# STM32WBA54 register map
File version: 1.0
CPU: CM33 r0p1, little endian, MPU, FPU, 4 interrupt priority bits
Registers are 32-bit, read-write, reset 0x0 unless marked. A register's access mark holds for its fields unless they carry their own. Offsets are from the block's base; [hi:lo] are bit positions; lines under a group give offsets from that group; {n}, {i} and the like mark numbered series; 'fields as' and 'values as' point back to an identical list.

## TSC — Touch sensing controller
Base 0x40024000
Same registers: SEC_TSC 0x50024000
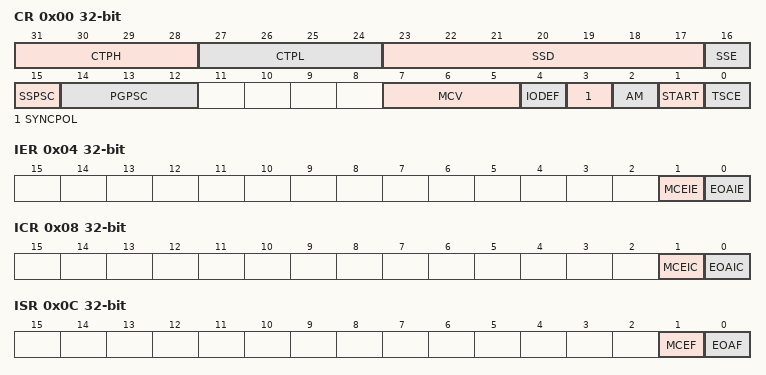
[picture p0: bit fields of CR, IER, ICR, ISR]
0x00 CR — TSC control register
  [31:28] CTPH — Charge transfer pulse high These bits are set and cleared by software. They define the duration of the high state of the charge transfer pulse (charge of CsubX/sub). ... Note: These bits must not be modified when an acquisition is ongoing.
  [27:24] CTPL — Charge transfer pulse low These bits are set and cleared by software. They define the duration of the low state of the charge transfer pulse (transfer of charge from CsubX/sub to CsubS/sub). ... Note: These bits must not be modified when an acquisition is ongoing. Note: Some configurations are forbidden. Refer to the Section21.3.4: Charge transfer acquisition sequence for details.
  [23:17] SSD — Spread spectrum deviation These bits are set and cleared by software. They define the spread spectrum deviation which consists in adding a variable number of periods of the SSCLK clock to the charge transfer pulse high state. ... Note: These bits must not be modified when an acquisition is ongoing.
  [16] SSE — Spread spectrum enable This bit is set and cleared by software to enable/disable the spread spectrum feature. Note: This bit must not be modified when an acquisition is ongoing.
    0=Disabled (Spread spectrum disabled); 1=Enabled (Spread spectrum enabled)
  [15] SSPSC — Spread spectrum prescaler This bit is set and cleared by software. It selects the AHB clock divider used to generate the spread spectrum clock (SSCLK). Note: This bit must not be modified when an acquisition is ongoing.
  [14:12] PGPSC — Pulse generator prescaler These bits are set and cleared by software.They select the AHB clock divider used to generate the pulse generator clock (PGCLK). Note: These bits must not be modified when an acquisition is ongoing. Note: Some configurations are forbidden. Refer to the Section21.3.4: Charge transfer acquisition sequence for details.
  [7:5] MCV — Max count value These bits are set and cleared by software. They define the maximum number of charge transfer pulses that can be generated before a max count error is generated. Note: These bits must not be modified when an acquisition is ongoing.
  [4] IODEF — I/O Default mode This bit is set and cleared by software. It defines the configuration of all the TSC I/Os when there is no ongoing acquisition. When there is an ongoing acquisition, it defines the configuration of all unused I/Os (not defined as sampling capacitor I/O or as channel I/O). Note: This bit must not be modified when an acquisition is ongoing.
    0=PushPull (I/Os are forced to output push-pull low); 1=Floating (I/Os are in input floating)
  [3] SYNCPOL — Synchronization pin polarity This bit is set and cleared by software to select the polarity of the synchronization input pin.
    0=Falling edge only; 1=Rising edge and high level
  [2] AM — Acquisition mode This bit is set and cleared by software to select the acquisition mode. Note: This bit must not be modified when an acquisition is ongoing.
    0=Normal acquisition mode (acquisition starts as soon as START bit is set); 1=Synchronized acquisition mode (acquisition starts if START bit is set and when the selected signal is detected on the SYNC input pin)
  [1] START — Start a new acquisition This bit is set by software to start a new acquisition. It is cleared by hardware as soon as the acquisition is complete or by software to cancel the ongoing acquisition.
    0=NoStarted (Acquisition not started); 1=Started (Start a new acquisition)
  [0] TSCE — Touch sensing controller enable This bit is set and cleared by software to enable/disable the touch sensing controller. Note: When the touch sensing controller is disabled, TSC registers settings have no effect.
    0=Disabled (Touch sensing controller disabled); 1=Enabled (Touch sensing controller enabled)
0x04 IER — TSC interrupt enable register
  [1] MCEIE — Max count error interrupt enable This bit is set and cleared by software to enable/disable the max count error interrupt.
    0=Disabled (Max count error interrupt disabled); 1=Enabled (Max count error interrupt enabled)
  [0] EOAIE — End of acquisition interrupt enable This bit is set and cleared by software to enable/disable the end of acquisition interrupt.
    0=Disabled (End of acquisition interrupt disabled); 1=Enabled (End of acquisition interrupt enabled)
0x08 ICR — TSC interrupt clear register
  [1] MCEIC — Max count error interrupt clear This bit is set by software to clear the max count error flag and it is cleared by hardware when the flag is reset. Writing a '0' has no effect.
  [0] EOAIC — End of acquisition interrupt clear This bit is set by software to clear the end of acquisition flag and it is cleared by hardware when the flag is reset. Writing a '0' has no effect.
0x0C ISR ro — TSC interrupt status register
  [1] MCEF — Max count error flag This bit is set by hardware as soon as an analog I/O group counter reaches the max count value specified. It is cleared by software writing 1 to the bit MCEIC of the TSC_ICR register.
  [0] EOAF — End of acquisition flag This bit is set by hardware when the acquisition of all enabled group is complete (all GxS bits of all enabled analog I/O groups are set or when a max count error is detected). It is cleared by software writing 1 to the bit EOAIC of the TSC_ICR register.
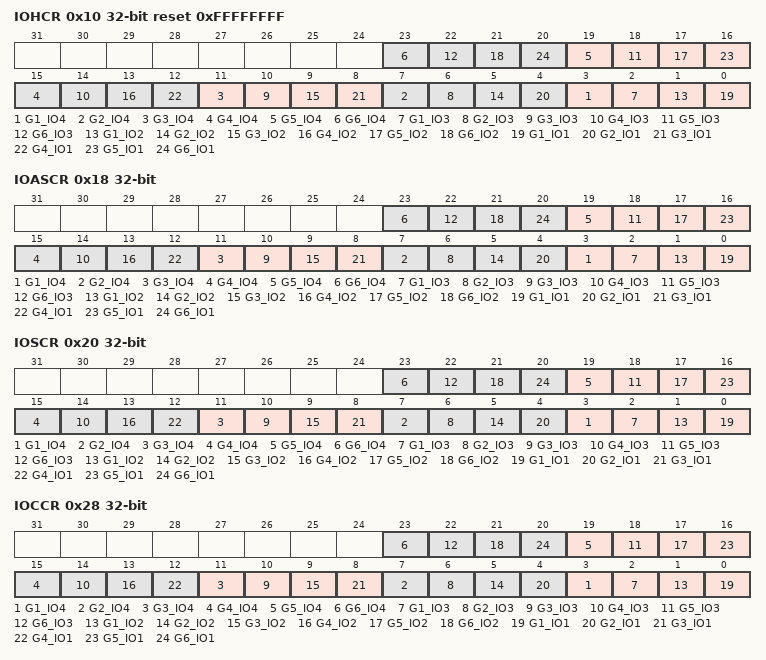
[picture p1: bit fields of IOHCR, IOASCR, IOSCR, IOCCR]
0x10 IOHCR reset 0xFFFFFFFF — TSC I/O hysteresis control register
  [all] fields
    0=Disabled (Gx_IOy Schmitt trigger hysteresis disabled); 1=Enabled (Gx_IOy Schmitt trigger hysteresis enabled)
  [4n-1] G{n}_IO4 (n=1..6) — Gx_IOy Schmitt trigger hysteresis mode, x = 8 to 1, y = 4 to 1. These bits are set and cleared by software to enable/disable the Gx_IOy Schmitt trigger hysteresis. Note: These bits control the I/O Schmitt trigger hysteresis whatever the I/O control mode is (even if controlled by standard GPIO registers).
  [4n-2] G{n}_IO3 (n=1..6) — Gx_IOy Schmitt trigger hysteresis mode, x = 8 to 1, y = 4 to 1. These bits are set and cleared by software to enable/disable the Gx_IOy Schmitt trigger hysteresis. Note: These bits control the I/O Schmitt trigger hysteresis whatever the I/O control mode is (even if controlled by standard GPIO registers).
  [4n-3] G{n}_IO2 (n=1..6) — Gx_IOy Schmitt trigger hysteresis mode, x = 8 to 1, y = 4 to 1. These bits are set and cleared by software to enable/disable the Gx_IOy Schmitt trigger hysteresis. Note: These bits control the I/O Schmitt trigger hysteresis whatever the I/O control mode is (even if controlled by standard GPIO registers).
  [4n-4] G{n}_IO1 (n=1..6) — Gx_IOy Schmitt trigger hysteresis mode, x = 8 to 1, y = 4 to 1. These bits are set and cleared by software to enable/disable the Gx_IOy Schmitt trigger hysteresis. Note: These bits control the I/O Schmitt trigger hysteresis whatever the I/O control mode is (even if controlled by standard GPIO registers).
0x18 IOASCR — TSC I/O analog switch control register
  [4n-1] G{n}_IO4 (n=1..6) — Gx_IOy analog switch enable These bits are set and cleared by software to enable/disable the Gx_IOy analog switch. Note: These bits control the I/O analog switch whatever the I/O control mode is (even if controlled by standard GPIO registers).
    values as the fields of IOHCR
  [4n-2] G{n}_IO3 (n=1..6) — Gx_IOy analog switch enable These bits are set and cleared by software to enable/disable the Gx_IOy analog switch. Note: These bits control the I/O analog switch whatever the I/O control mode is (even if controlled by standard GPIO registers).
    values as the fields of IOHCR
  [4n-3] G{n}_IO2 (n=1..6) — Gx_IOy analog switch enable These bits are set and cleared by software to enable/disable the Gx_IOy analog switch. Note: These bits control the I/O analog switch whatever the I/O control mode is (even if controlled by standard GPIO registers).
    values as the fields of IOHCR
  [4n-4] G{n}_IO1 (n=1..6) — Gx_IOy analog switch enable These bits are set and cleared by software to enable/disable the Gx_IOy analog switch. Note: These bits control the I/O analog switch whatever the I/O control mode is (even if controlled by standard GPIO registers).
    0=Disabled (Gx_IOy analog switch disabled (opened)); 1=Enabled (Gx_IOy analog switch enabled (closed))
0x20 IOSCR — TSC I/O sampling control register
  [4n-1] G{n}_IO4 (n=1..6) — Gx_IOy sampling mode These bits are set and cleared by software to configure the Gx_IOy as a sampling capacitor I/O. Only one I/O per analog I/O group must be defined as sampling capacitor. Note: These bits must not be modified when an acquisition is ongoing. Note: During the acquisition phase and even if the TSC peripheral alternate function is not enabled, as soon as the TSC_IOSCR bit is set, the corresponding GPIO analog switch is automatically controlled by the touch sensing controller.
    values as the fields of IOHCR
  [4n-2] G{n}_IO3 (n=1..6) — Gx_IOy sampling mode These bits are set and cleared by software to configure the Gx_IOy as a sampling capacitor I/O. Only one I/O per analog I/O group must be defined as sampling capacitor. Note: These bits must not be modified when an acquisition is ongoing. Note: During the acquisition phase and even if the TSC peripheral alternate function is not enabled, as soon as the TSC_IOSCR bit is set, the corresponding GPIO analog switch is automatically controlled by the touch sensing controller.
    values as the fields of IOHCR
  [4n-3] G{n}_IO2 (n=1..6) — Gx_IOy sampling mode These bits are set and cleared by software to configure the Gx_IOy as a sampling capacitor I/O. Only one I/O per analog I/O group must be defined as sampling capacitor. Note: These bits must not be modified when an acquisition is ongoing. Note: During the acquisition phase and even if the TSC peripheral alternate function is not enabled, as soon as the TSC_IOSCR bit is set, the corresponding GPIO analog switch is automatically controlled by the touch sensing controller.
    values as the fields of IOHCR
  [4n-4] G{n}_IO1 (n=1..6) — Gx_IOy sampling mode These bits are set and cleared by software to configure the Gx_IOy as a sampling capacitor I/O. Only one I/O per analog I/O group must be defined as sampling capacitor. Note: These bits must not be modified when an acquisition is ongoing. Note: During the acquisition phase and even if the TSC peripheral alternate function is not enabled, as soon as the TSC_IOSCR bit is set, the corresponding GPIO analog switch is automatically controlled by the touch sensing controller.
    0=Disabled (Gx_IOy unused); 1=Enabled (Gx_IOy used as sampling capacitor)
0x28 IOCCR — TSC I/O channel control register
  [4n-1] G{n}_IO4 (n=1..6) — Gx_IOy channel mode These bits are set and cleared by software to configure the Gx_IOy as a channel I/O. Note: These bits must not be modified when an acquisition is ongoing. Note: During the acquisition phase and even if the TSC peripheral alternate function is not enabled, as soon as the TSC_IOCCR bit is set, the corresponding GPIO analog switch is automatically controlled by the touch sensing controller.
    values as the fields of IOHCR
  [4n-2] G{n}_IO3 (n=1..6) — Gx_IOy channel mode These bits are set and cleared by software to configure the Gx_IOy as a channel I/O. Note: These bits must not be modified when an acquisition is ongoing. Note: During the acquisition phase and even if the TSC peripheral alternate function is not enabled, as soon as the TSC_IOCCR bit is set, the corresponding GPIO analog switch is automatically controlled by the touch sensing controller.
    values as the fields of IOHCR
  [4n-3] G{n}_IO2 (n=1..6) — Gx_IOy channel mode These bits are set and cleared by software to configure the Gx_IOy as a channel I/O. Note: These bits must not be modified when an acquisition is ongoing. Note: During the acquisition phase and even if the TSC peripheral alternate function is not enabled, as soon as the TSC_IOCCR bit is set, the corresponding GPIO analog switch is automatically controlled by the touch sensing controller.
    values as the fields of IOHCR
  [4n-4] G{n}_IO1 (n=1..6) — Gx_IOy channel mode These bits are set and cleared by software to configure the Gx_IOy as a channel I/O. Note: These bits must not be modified when an acquisition is ongoing. Note: During the acquisition phase and even if the TSC peripheral alternate function is not enabled, as soon as the TSC_IOCCR bit is set, the corresponding GPIO analog switch is automatically controlled by the touch sensing controller.
    0=Disabled (Gx_IOy unused); 1=Enabled (Gx_IOy used as channel)
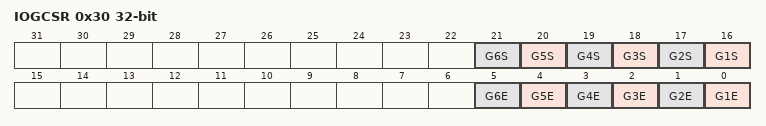
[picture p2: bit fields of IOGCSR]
0x30 IOGCSR access per field — TSC I/O group control status register
  [n+15] G{n}S (n=1..6) ro — Analog I/O group x status These bits are set by hardware when the acquisition on the corresponding enabled analog I/O group x is complete. They are cleared by hardware when a new acquisition is started. Note: When a max count error is detected the remaining GxS bits of the enabled analog I/O groups are not set.
    0=Ongoing (Acquisition on analog I/O group x is ongoing or not started); 1=Complete (Acquisition on analog I/O group x is complete)
  [n-1] G{n}E (n=1..6) rw — Analog I/O group x enable These bits are set and cleared by software to enable/disable the acquisition (counter is counting) on the corresponding analog I/O group x.
    0=Disabled (Acquisition on analog I/O group x disabled); 1=Enabled (Acquisition on analog I/O group x enabled)
{0x30+4i} IOG{i}CR (i=1..6) ro — TSC I/O group {i} counter register
  [13:0] CNT — Counter value These bits represent the number of charge transfer cycles generated on the analog I/O group x to complete its acquisition (voltage across CsubS/sub has reached the threshold).
